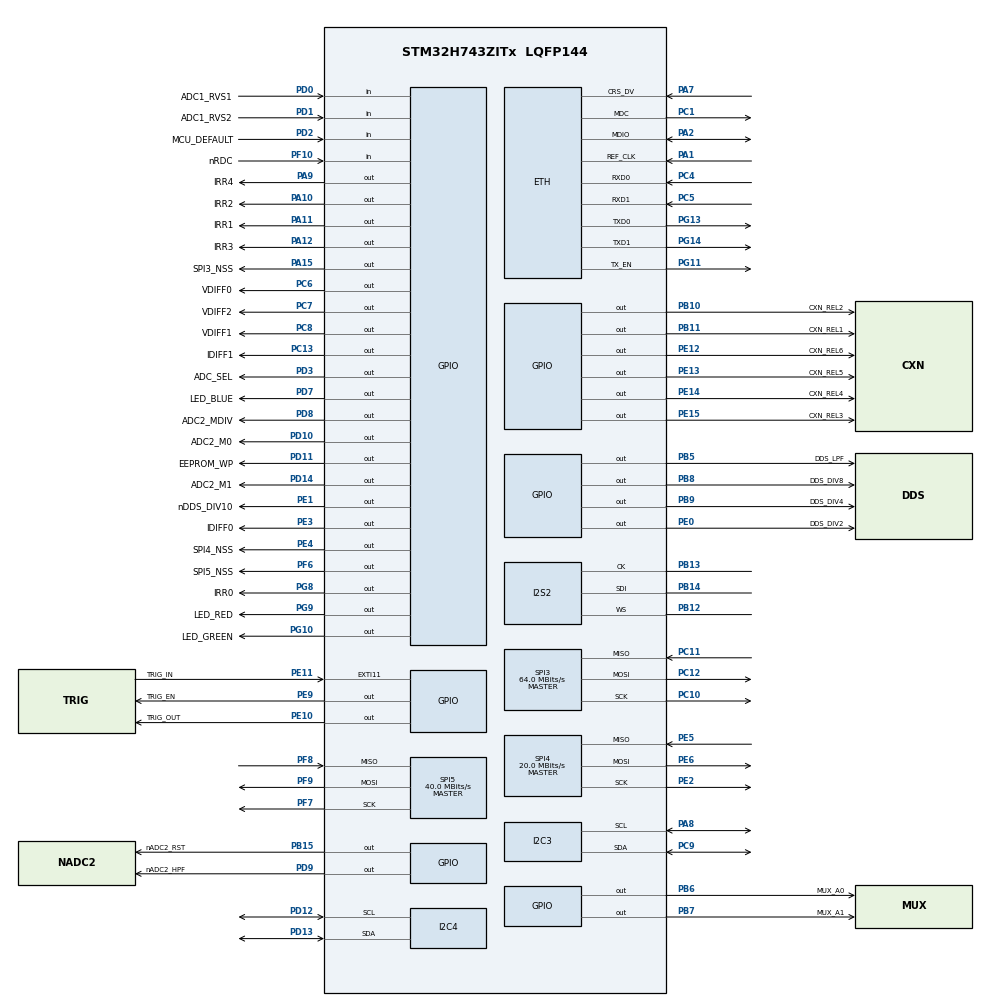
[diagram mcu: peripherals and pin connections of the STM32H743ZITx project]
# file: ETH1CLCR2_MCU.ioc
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CORTEX_M7.AccessPermission-Cortex_Memory_Protection_Unit_Region0_Settings=MPU_REGION_FULL_ACCESS
CORTEX_M7.AccessPermission-Cortex_Memory_Protection_Unit_Region1_Settings=MPU_REGION_FULL_ACCESS
CORTEX_M7.BaseAddress-Cortex_Memory_Protection_Unit_Region0_Settings=0x30040000
CORTEX_M7.BaseAddress-Cortex_Memory_Protection_Unit_Region1_Settings=0x30040000
CORTEX_M7.CPU_DCache=Enabled
CORTEX_M7.CPU_ICache=Enabled
CORTEX_M7.DisableExec-Cortex_Memory_Protection_Unit_Region0_Settings=MPU_INSTRUCTION_ACCESS_DISABLE
CORTEX_M7.DisableExec-Cortex_Memory_Protection_Unit_Region1_Settings=MPU_INSTRUCTION_ACCESS_DISABLE
CORTEX_M7.Enable-Cortex_Memory_Protection_Unit_Region0_Settings=MPU_REGION_ENABLE
CORTEX_M7.Enable-Cortex_Memory_Protection_Unit_Region1_Settings=MPU_REGION_ENABLE
CORTEX_M7.IsBufferable-Cortex_Memory_Protection_Unit_Region1_Settings=MPU_ACCESS_BUFFERABLE
CORTEX_M7.IsShareable-Cortex_Memory_Protection_Unit_Region1_Settings=MPU_ACCESS_SHAREABLE
CORTEX_M7.MPU_Control=MPU_PRIVILEGED_DEFAULT
CORTEX_M7.Size-Cortex_Memory_Protection_Unit_Region0_Settings=MPU_REGION_SIZE_32KB
CORTEX_M7.Size-Cortex_Memory_Protection_Unit_Region1_Settings=MPU_REGION_SIZE_256B
CORTEX_M7.TypeExtField-Cortex_Memory_Protection_Unit_Region0_Settings=MPU_TEX_LEVEL1
ETH.MediaInterface=HAL_ETH_RMII_MODE
FREERTOS.Queues01=QueueTrigger,1,uint8_t,0,Static,QueueTriggerBuffer,QueueTriggerControlBlock
FREERTOS.Tasks01=defaultTask,24,128,StartDefaultTask,Default,NULL,Dynamic,NULL,NULL;LEDTask,8,256,StartLEDTask,Default,NULL,Dynamic,NULL,NULL;TriggerTask,40,128,StartTriggerTask,Default,NULL,Dynamic,NULL,NULL
FREERTOS.configUSE_NEWLIB_REENTRANT=1
I2C3.Timing=0x00C0EAFF
I2C4.Timing=0x10C0ECFF
I2S2.AudioFreq=AudioFreqCustomValue
I2S2.AudioFreqCustom=64062
I2S2.CPOL=I2S_CPOL_LOW
I2S2.Data24BitAlignment=I2S_DATA_24BIT_ALIGNMENT_RIGHT
I2S2.DataFormat=I2S_DATAFORMAT_24B
I2S2.ErrorAudioFreq=0.8 %
I2S2.Instance=SPI$Index
I2S2.MasterKeepIOState=I2S_MASTER_KEEP_IO_STATE_DISABLE
I2S2.RealAudioFreq=64.516 KHz
I2S2.Standard=I2S_STANDARD_PHILIPS
LWIP.BSP.number=1
LWIP.GATEWAY_ADDRESS=192.168.001.001
LWIP.IP_ADDRESS=192.168.001.126
LWIP.LWIP_DHCP=0
LWIP.MEM_SIZE=16360
LWIP.NETMASK_ADDRESS=255.255.255.000
LWIP.TCPIP_THREAD_STACKSIZE=2048
LWIP.Version=v2.1.2_Cube
LWIP0.BSP.STBoard=false
LWIP0.BSP.api=BSP_COMPONENT_DRIVER
LWIP0.BSP.component=LAN8742
LWIP0.BSP.instance=LAN8742
LWIP0.BSP.name=Driver_PHY
LWIP0.BSP.solution=LAN8742
Mcu.Family=STM32H7
Mcu.Name=STM32H743ZITx
Mcu.Package=LQFP144
NVIC.ETH_IRQn=true\:5\:0\:false\:false\:true\:true\:true\:true\:true
NVIC.EXTI15_10_IRQn=true\:5\:0\:false\:false\:true\:true\:true\:true\:true
NVIC.PriorityGroup=NVIC_PRIORITYGROUP_4
NVIC.TIM1_UP_IRQn=true\:15\:0\:false\:false\:true\:false\:false\:true\:true
NVIC.TimeBase=TIM1_UP_IRQn
NVIC.TimeBaseIP=TIM1
PA1.GPIO_Speed=GPIO_SPEED_FREQ_VERY_HIGH
PA1.Mode=RMII
PA1.Signal=ETH_REF_CLK
PA10.GPIO_Label=IRR2
PA10.PinState=GPIO_PIN_SET
PA10.Signal=GPIO_Output
PA11.GPIO_Label=IRR1
PA11.PinState=GPIO_PIN_SET
PA11.Signal=GPIO_Output
PA12.GPIO_Label=IRR3
PA12.PinState=GPIO_PIN_SET
PA12.Signal=GPIO_Output
PA13\ (JTMS/SWDIO).Signal=DEBUG_JTMS-SWDIO
PA14\ (JTCK/SWCLK).Signal=DEBUG_JTCK-SWCLK
PA15\ (JTDI).GPIO_Label=SPI3_NSS
PA15\ (JTDI).GPIO_PuPd=GPIO_PULLUP
PA15\ (JTDI).GPIO_Speed=GPIO_SPEED_FREQ_VERY_HIGH
PA15\ (JTDI).PinState=GPIO_PIN_SET
PA15\ (JTDI).Signal=GPIO_Output
PA2.GPIO_Speed=GPIO_SPEED_FREQ_VERY_HIGH
PA2.Mode=RMII
PA2.Signal=ETH_MDIO
PA7.GPIO_Speed=GPIO_SPEED_FREQ_VERY_HIGH
PA7.Mode=RMII
PA7.Signal=ETH_CRS_DV
PA8.GPIO_Pu=GPIO_PULLUP
PA8.Mode=I2C
PA8.Signal=I2C3_SCL
PA9.GPIO_Label=IRR4
PA9.Signal=GPIO_Output
PB10.GPIO_Label=CXN_REL2
PB10.Signal=GPIO_Output
PB11.GPIO_Label=CXN_REL1
PB11.Signal=GPIO_Output
PB12.GPIO_Speed=GPIO_SPEED_FREQ_HIGH
PB12.Mode=Half_Duplex_Master_Rx
PB12.Signal=I2S2_WS
PB13.GPIO_Speed=GPIO_SPEED_FREQ_HIGH
PB13.Mode=Half_Duplex_Master_Rx
PB13.Signal=I2S2_CK
PB14.GPIO_PuPd=GPIO_NOPULL
PB14.GPIO_Speed=GPIO_SPEED_FREQ_HIGH
PB14.Mode=Half_Duplex_Master_Rx
PB14.Signal=I2S2_SDI
PB15.GPIO_Label=nADC2_RST
PB15.Signal=GPIO_Output
PB5.GPIO_Label=DDS_LPF
PB5.Signal=GPIO_Output
PB6.GPIO_Label=MUX_A0
PB6.Signal=GPIO_Output
PB7.GPIO_Label=MUX_A1
PB7.Signal=GPIO_Output
PB8.GPIO_Label=DDS_DIV8
PB8.PinState=GPIO_PIN_SET
PB8.Signal=GPIO_Output
PB9.GPIO_Label=DDS_DIV4
PB9.PinState=GPIO_PIN_SET
PB9.Signal=GPIO_Output
PC1.Mode=RMII
PC1.Signal=ETH_MDC
PC10.GPIO_Speed=GPIO_SPEED_FREQ_HIGH
PC10.Mode=Full_Duplex_Master
PC10.Signal=SPI3_SCK
PC11.GPIO_Speed=GPIO_SPEED_FREQ_HIGH
PC11.Mode=Full_Duplex_Master
PC11.Signal=SPI3_MISO
PC12.GPIO_Speed=GPIO_SPEED_FREQ_HIGH
PC12.Mode=Full_Duplex_Master
PC12.Signal=SPI3_MOSI
PC13.GPIO_Label=IDIFF1
PC13.Signal=GPIO_Output
PC4.GPIO_Speed=GPIO_SPEED_FREQ_VERY_HIGH
PC4.Mode=RMII
PC4.Signal=ETH_RXD0
PC5.GPIO_Speed=GPIO_SPEED_FREQ_VERY_HIGH
PC5.Mode=RMII
PC5.Signal=ETH_RXD1
PC6.GPIO_Label=VDIFF0
PC6.Signal=GPIO_Output
PC7.GPIO_Label=VDIFF2
PC7.Signal=GPIO_Output
PC8.GPIO_Label=VDIFF1
PC8.PinState=GPIO_PIN_RESET
PC8.Signal=GPIO_Output
PC9.GPIO_Pu=GPIO_PULLUP
PC9.Mode=I2C
PC9.Signal=I2C3_SDA
PD0.GPIO_Label=ADC1_RVS1
PD0.Signal=GPIO_Input
PD1.GPIO_Label=ADC1_RVS2
PD1.Signal=GPIO_Input
PD10.GPIO_Label=ADC2_M0
PD10.Signal=GPIO_Output
PD11.GPIO_Label=EEPROM_WP
PD11.Signal=GPIO_Output
PD12.GPIO_Pu=GPIO_PULLUP
PD12.Mode=I2C
PD12.Signal=I2C4_SCL
PD13.GPIO_Pu=GPIO_PULLUP
PD13.Mode=I2C
PD13.Signal=I2C4_SDA
PD14.GPIO_Label=ADC2_M1
PD14.Signal=GPIO_Output
PD2.GPIO_Label=MCU_DEFAULT
PD2.Signal=GPIO_Input
PD3.GPIO_Label=ADC_SEL
PD3.GPIO_Speed=GPIO_SPEED_FREQ_LOW
PD3.PinState=GPIO_PIN_RESET
PD3.Signal=GPIO_Output
PD7.GPIO_Label=LED_BLUE
PD7.PinState=GPIO_PIN_SET
PD7.Signal=GPIO_Output
PD8.GPIO_Label=ADC2_MDIV
PD8.Signal=GPIO_Output
PD9.GPIO_Label=nADC2_HPF
PD9.Signal=GPIO_Output
PE0.GPIO_Label=DDS_DIV2
PE0.PinState=GPIO_PIN_SET
PE0.Signal=GPIO_Output
PE1.GPIO_Label=nDDS_DIV10
PE1.PinState=GPIO_PIN_SET
PE1.Signal=GPIO_Output
PE10.GPIO_Label=TRIG_OUT
PE10.Signal=GPIO_Output
PE11.GPIO_Label=TRIG_IN
PE11.Signal=GPXTI11
PE12.GPIO_Label=CXN_REL6
PE12.Signal=GPIO_Output
PE13.GPIO_Label=CXN_REL5
PE13.Signal=GPIO_Output
PE14.GPIO_Label=CXN_REL4
PE14.Signal=GPIO_Output
PE15.GPIO_Label=CXN_REL3
PE15.Signal=GPIO_Output
PE2.GPIO_PuPd=GPIO_PULLUP
PE2.GPIO_Speed=GPIO_SPEED_FREQ_HIGH
PE2.Mode=Full_Duplex_Master
PE2.Signal=SPI4_SCK
PE3.GPIO_Label=IDIFF0
PE3.Signal=GPIO_Output
PE4.GPIO_Label=SPI4_NSS
PE4.GPIO_PuPd=GPIO_PULLUP
PE4.GPIO_Speed=GPIO_SPEED_FREQ_HIGH
PE4.PinState=GPIO_PIN_SET
PE4.Signal=GPIO_Output
PE5.GPIO_Speed=GPIO_SPEED_FREQ_HIGH
PE5.Mode=Full_Duplex_Master
PE5.Signal=SPI4_MISO
PE6.GPIO_Speed=GPIO_SPEED_FREQ_HIGH
PE6.Mode=Full_Duplex_Master
PE6.Signal=SPI4_MOSI
PE9.GPIO_Label=TRIG_EN
PE9.PinState=GPIO_PIN_SET
PE9.Signal=GPIO_Output
PF10.GPIO_Label=nRDC
PF10.Signal=GPIO_Input
PF6.GPIO_Label=SPI5_NSS
PF6.GPIO_PuPd=GPIO_PULLUP
PF6.PinState=GPIO_PIN_SET
PF6.Signal=GPIO_Output
PF7.GPIO_Speed=GPIO_SPEED_FREQ_HIGH
PF7.Mode=Full_Duplex_Master
PF7.Signal=SPI5_SCK
PF8.GPIO_Speed=GPIO_SPEED_FREQ_HIGH
PF8.Mode=Full_Duplex_Master
PF8.Signal=SPI5_MISO
PF9.GPIO_Speed=GPIO_SPEED_FREQ_HIGH
PF9.Mode=Full_Duplex_Master
PF9.Signal=SPI5_MOSI
PG10.GPIO_Label=LED_GREEN
PG10.PinState=GPIO_PIN_SET
PG10.Signal=GPIO_Output
PG11.GPIO_Speed=GPIO_SPEED_FREQ_VERY_HIGH
PG11.Mode=RMII
PG11.Signal=ETH_TX_EN
PG13.GPIO_Speed=GPIO_SPEED_FREQ_VERY_HIGH
PG13.Mode=RMII
PG13.Signal=ETH_TXD0
PG14.GPIO_Speed=GPIO_SPEED_FREQ_VERY_HIGH
PG14.Mode=RMII
PG14.Signal=ETH_TXD1
PG8.GPIO_Label=IRR0
PG8.PinState=GPIO_PIN_RESET
PG8.Signal=GPIO_Output
PG9.GPIO_Label=LED_RED
PG9.PinState=GPIO_PIN_SET
PG9.Signal=GPIO_Output
PH0-OSC_IN\ (PH0).Mode=HSE-External-Oscillator
PH0-OSC_IN\ (PH0).Signal=RCC_OSC_IN
PH1-OSC_OUT\ (PH1).Mode=HSE-External-Oscillator
PH1-OSC_OUT\ (PH1).Signal=RCC_OSC_OUT
ProjectManager.HeapSize=0x200
ProjectManager.StackSize=0x400
ProjectManager.TargetToolchain=STM32CubeIDE
RCC.ADCFreq_Value=128000000
RCC.APB1Freq_Value=50000000
RCC.APB2Freq_Value=100000000
RCC.APB3Freq_Value=100000000
RCC.APB4Freq_Value=100000000
RCC.CortexFreq_Value=400000000
RCC.D1PPRE=RCC_APB3_DIV2
RCC.D2PPRE1=RCC_APB1_DIV4
RCC.D2PPRE2=RCC_APB2_DIV2
RCC.D3PPRE=RCC_APB4_DIV2
RCC.DIVM1=8
RCC.DIVM2=4
RCC.DIVM3=4
RCC.DIVN1=400
RCC.DIVN2=128
RCC.DIVN3=120
RCC.DIVP2=4
RCC.DIVQ1=4
RCC.DIVQ2=4
RCC.DIVQ3=6
RCC.EnbaleCSS=true
RCC.HCLKFreq_Value=200000000
RCC.HPRE=RCC_HCLK_DIV2
RCC.HSE_VALUE=16000000
RCC.PLL2FRACN=0
RCC.PLL3FRACN=0
RCC.PLLFRACN=0
RCC.PLLSourceVirtual=RCC_PLLSOURCE_HSE
RCC.SPI123CLockSelection=RCC_SPI123CLKSOURCE_PLL2
RCC.SYSCLKFreq_VALUE=400000000
RCC.SYSCLKSource=RCC_SYSCLKSOURCE_PLLCLK
RCC.Spi45ClockSelection=RCC_SPI45CLKSOURCE_PLL3
RCC.USBFreq_Value=200000000
SPI3.BaudRatePrescaler=SPI_BAUDRATEPRESCALER_2
SPI3.CalculateBaudRate=64.0 MBits/s
SPI3.DataSize=SPI_DATASIZE_32BIT
SPI3.Direction=SPI_DIRECTION_2LINES
SPI3.Mode=SPI_MODE_MASTER
SPI3.VirtualType=VM_MASTER
SPI4.BaudRatePrescaler=SPI_BAUDRATEPRESCALER_4
SPI4.CLKPhase=SPI_PHASE_1EDGE
SPI4.CLKPolarity=SPI_POLARITY_HIGH
SPI4.CalculateBaudRate=20.0 MBits/s
SPI4.DataSize=SPI_DATASIZE_16BIT
SPI4.Direction=SPI_DIRECTION_2LINES
SPI4.Mode=SPI_MODE_MASTER
SPI4.VirtualType=VM_MASTER
SPI5.BaudRatePrescaler=SPI_BAUDRATEPRESCALER_2
SPI5.CLKPhase=SPI_PHASE_2EDGE
SPI5.CalculateBaudRate=40.0 MBits/s
SPI5.DataSize=SPI_DATASIZE_16BIT
SPI5.Direction=SPI_DIRECTION_2LINES
SPI5.Mode=SPI_MODE_MASTER
SPI5.VirtualType=VM_MASTER
VP_FREERTOS_VS_CMSIS_V2.Mode=CMSIS_V2
VP_LWIP_VS_Enabled.Mode=Enabled
VP_SYS_VS_tim1.Mode=TIM1
board=custom

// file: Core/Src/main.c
/* USER CODE BEGIN Header */
/**
  ******************************************************************************
  * @file           : main.c
  * @brief          : Main program body
  ******************************************************************************
  * @attention
  *
  * <h2><center>&copy; Copyright (c) 2021 STMicroelectronics.
  * All rights reserved.</center></h2>
  *
  * This software component is licensed by ST under BSD 3-Clause license,
  * the "License"; You may not use this file except in compliance with the
  * License. You may obtain a copy of the License at:
  *                        opensource.org/licenses/BSD-3-Clause
  *
  ******************************************************************************
  */
/* USER CODE END Header */
#include "main.h"
#include "cmsis_os.h"
#include "lwip.h"

/* USER CODE BEGIN Includes */
#include "scpi_server.h"
#include "bsp.h"
#include "ADS8681.h"
#include "AD9834.h"
#include "dwt_delay.h"
#include "CS5361.h"
#include "IV_Converter.h"
#include "relays.h"
/* USER CODE END Includes */

typedef StaticQueue_t osStaticMessageQDef_t;

I2C_HandleTypeDef hi2c3;
I2C_HandleTypeDef hi2c4;

I2S_HandleTypeDef hi2s2;

SPI_HandleTypeDef hspi4;
SPI_HandleTypeDef hspi5;

/* Definitions for defaultTask */
osThreadId_t defaultTaskHandle;
const osThreadAttr_t defaultTask_attributes = {
  .name = "defaultTask",
  .stack_size = 128 * 4,
  .priority = (osPriority_t) osPriorityNormal,
};
/* Definitions for LEDTask */
osThreadId_t LEDTaskHandle;
const osThreadAttr_t LEDTask_attributes = {
  .name = "LEDTask",
  .stack_size = 256 * 4,
  .priority = (osPriority_t) osPriorityLow,
};
/* Definitions for TriggerTask */
osThreadId_t TriggerTaskHandle;
const osThreadAttr_t TriggerTask_attributes = {
  .name = "TriggerTask",
  .stack_size = 128 * 4,
  .priority = (osPriority_t) osPriorityHigh,
};
/* Definitions for QueueTrigger */
osMessageQueueId_t QueueTriggerHandle;
uint8_t QueueTriggerBuffer[ 1 * sizeof( uint8_t ) ];
osStaticMessageQDef_t QueueTriggerControlBlock;
const osMessageQueueAttr_t QueueTrigger_attributes = {
  .name = "QueueTrigger",
  .cb_mem = &QueueTriggerControlBlock,
  .cb_size = sizeof(QueueTriggerControlBlock),
  .mq_mem = &QueueTriggerBuffer,
  .mq_size = sizeof(QueueTriggerBuffer)
};

void SystemClock_Config(void);
void PeriphCommonClock_Config(void);
static void MPU_Config(void);
static void MX_GPIO_Init(void);
static void MX_I2C3_Init(void);
static void MX_I2C4_Init(void);
static void MX_SPI3_Init(void);
static void MX_SPI4_Init(void);
static void MX_SPI5_Init(void);
static void MX_I2S2_Init(void);
void StartDefaultTask(void *argument);
void StartLEDTask(void *argument);
void StartTriggerTask(void *argument);

int main(void)
{

  /* MPU Configuration--------------------------------------------------------*/
  MPU_Config();

  /* Enable I-Cache---------------------------------------------------------*/
  SCB_EnableICache();

  /* Enable D-Cache---------------------------------------------------------*/
  SCB_EnableDCache();

  /* MCU Configuration--------------------------------------------------------*/

  /* Reset of all peripherals, Initializes the Flash interface and the Systick. */
  HAL_Init();

  /* Configure the system clock */
  SystemClock_Config();

/* Configure the peripherals common clocks */
  PeriphCommonClock_Config();

  /* Initialize all configured peripherals */
  MX_GPIO_Init();
  MX_I2C3_Init();
  MX_I2C4_Init();
  MX_SPI3_Init();
  MX_SPI4_Init();
  MX_SPI5_Init();
  MX_I2S2_Init();
  /* USER CODE BEGIN 2 */
  HAL_Delay(100);
  MX_LWIP_Init();
  DWT_Init();
  BSP_Init();
  ADS8681_Init();
  AD9834_Init();
  CS5361_Init();
  IV_Converter(R1k);
  CXN_Relays_AllOn();
  /* USER CODE END 2 */

  /* Init scheduler */
  osKernelInitialize();

  /* Create the queue(s) */
  /* creation of QueueTrigger */
  QueueTriggerHandle = osMessageQueueNew (1, sizeof(uint8_t), &QueueTrigger_attributes);

  /* Create the thread(s) */
  /* creation of defaultTask */
  defaultTaskHandle = osThreadNew(StartDefaultTask, NULL, &defaultTask_attributes);

  /* creation of LEDTask */
  LEDTaskHandle = osThreadNew(StartLEDTask, NULL, &LEDTask_attributes);

  /* creation of TriggerTask */
  TriggerTaskHandle = osThreadNew(StartTriggerTask, NULL, &TriggerTask_attributes);

  /* USER CODE BEGIN RTOS_THREADS */
  /* add threads, ... */
  scpi_server_init();
  osThreadSuspend(TriggerTaskHandle);
  /* USER CODE END RTOS_THREADS */

  /* Start scheduler */
  osKernelStart();

  /* We should never get here as control is now taken by the scheduler */
  /* Infinite loop */
  while (1)
  {

  }
}

void SystemClock_Config(void)
{
  RCC_OscInitTypeDef RCC_OscInitStruct = {0};
  RCC_ClkInitTypeDef RCC_ClkInitStruct = {0};

  /** Supply configuration update enable
  */
  HAL_PWREx_ConfigSupply(PWR_LDO_SUPPLY);

  /** Configure the main internal regulator output voltage
  */
  __HAL_PWR_VOLTAGESCALING_CONFIG(PWR_REGULATOR_VOLTAGE_SCALE1);

  while(!__HAL_PWR_GET_FLAG(PWR_FLAG_VOSRDY)) {}

  /** Macro to configure the PLL clock source
  */
  __HAL_RCC_PLL_PLLSOURCE_CONFIG(RCC_PLLSOURCE_HSE);

  /** Initializes the RCC Oscillators according to the specified parameters
  * in the RCC_OscInitTypeDef structure.
  */
  RCC_OscInitStruct.OscillatorType = RCC_OSCILLATORTYPE_HSE;
  RCC_OscInitStruct.HSEState = RCC_HSE_ON;
  RCC_OscInitStruct.PLL.PLLState = RCC_PLL_ON;
  RCC_OscInitStruct.PLL.PLLSource = RCC_PLLSOURCE_HSE;
  RCC_OscInitStruct.PLL.PLLM = 8;
  RCC_OscInitStruct.PLL.PLLN = 400;
  RCC_OscInitStruct.PLL.PLLP = 2;
  RCC_OscInitStruct.PLL.PLLQ = 4;
  RCC_OscInitStruct.PLL.PLLR = 2;
  RCC_OscInitStruct.PLL.PLLRGE = RCC_PLL1VCIRANGE_1;
  RCC_OscInitStruct.PLL.PLLVCOSEL = RCC_PLL1VCOWIDE;
  RCC_OscInitStruct.PLL.PLLFRACN = 0;
  if (HAL_RCC_OscConfig(&RCC_OscInitStruct) != HAL_OK)
  {
    Error_Handler();
  }

  /** Initializes the CPU, AHB and APB buses clocks
  */
  RCC_ClkInitStruct.ClockType = RCC_CLOCKTYPE_HCLK|RCC_CLOCKTYPE_SYSCLK
                              |RCC_CLOCKTYPE_PCLK1|RCC_CLOCKTYPE_PCLK2
                              |RCC_CLOCKTYPE_D3PCLK1|RCC_CLOCKTYPE_D1PCLK1;
  RCC_ClkInitStruct.SYSCLKSource = RCC_SYSCLKSOURCE_PLLCLK;
  RCC_ClkInitStruct.SYSCLKDivider = RCC_SYSCLK_DIV1;
  RCC_ClkInitStruct.AHBCLKDivider = RCC_HCLK_DIV2;
  RCC_ClkInitStruct.APB3CLKDivider = RCC_APB3_DIV2;
  RCC_ClkInitStruct.APB1CLKDivider = RCC_APB1_DIV4;
  RCC_ClkInitStruct.APB2CLKDivider = RCC_APB2_DIV2;
  RCC_ClkInitStruct.APB4CLKDivider = RCC_APB4_DIV2;

  if (HAL_RCC_ClockConfig(&RCC_ClkInitStruct, FLASH_LATENCY_2) != HAL_OK)
  {
    Error_Handler();
  }

  /** Enables the Clock Security System
  */
  HAL_RCC_EnableCSS();
}

void PeriphCommonClock_Config(void)
{
  RCC_PeriphCLKInitTypeDef PeriphClkInitStruct = {0};

  /** Initializes the peripherals clock
  */
  PeriphClkInitStruct.PeriphClockSelection = RCC_PERIPHCLK_SPI3|RCC_PERIPHCLK_SPI2
                              |RCC_PERIPHCLK_SPI4|RCC_PERIPHCLK_SPI5;
  PeriphClkInitStruct.PLL2.PLL2M = 4;
  PeriphClkInitStruct.PLL2.PLL2N = 128;
  PeriphClkInitStruct.PLL2.PLL2P = 4;
  PeriphClkInitStruct.PLL2.PLL2Q = 4;
  PeriphClkInitStruct.PLL2.PLL2R = 2;
  PeriphClkInitStruct.PLL2.PLL2RGE = RCC_PLL2VCIRANGE_2;
  PeriphClkInitStruct.PLL2.PLL2VCOSEL = RCC_PLL2VCOWIDE;
  PeriphClkInitStruct.PLL2.PLL2FRACN = 0;
  PeriphClkInitStruct.PLL3.PLL3M = 4;
  PeriphClkInitStruct.PLL3.PLL3N = 120;
  PeriphClkInitStruct.PLL3.PLL3P = 2;
  PeriphClkInitStruct.PLL3.PLL3Q = 6;
  PeriphClkInitStruct.PLL3.PLL3R = 2;
  PeriphClkInitStruct.PLL3.PLL3RGE = RCC_PLL3VCIRANGE_2;
  PeriphClkInitStruct.PLL3.PLL3VCOSEL = RCC_PLL3VCOWIDE;
  PeriphClkInitStruct.PLL3.PLL3FRACN = 0;
  PeriphClkInitStruct.Spi123ClockSelection = RCC_SPI123CLKSOURCE_PLL2;
  PeriphClkInitStruct.Spi45ClockSelection = RCC_SPI45CLKSOURCE_PLL3;
  if (HAL_RCCEx_PeriphCLKConfig(&PeriphClkInitStruct) != HAL_OK)
  {
    Error_Handler();
  }
}

static void MX_I2C3_Init(void)
{

  hi2c3.Instance = I2C3;
  hi2c3.Init.Timing = 0x00C0EAFF;
  hi2c3.Init.OwnAddress1 = 0;
  hi2c3.Init.AddressingMode = I2C_ADDRESSINGMODE_7BIT;
  hi2c3.Init.DualAddressMode = I2C_DUALADDRESS_DISABLE;
  hi2c3.Init.OwnAddress2 = 0;
  hi2c3.Init.OwnAddress2Masks = I2C_OA2_NOMASK;
  hi2c3.Init.GeneralCallMode = I2C_GENERALCALL_DISABLE;
  hi2c3.Init.NoStretchMode = I2C_NOSTRETCH_DISABLE;
  if (HAL_I2C_Init(&hi2c3) != HAL_OK)
  {
    Error_Handler();
  }

  /** Configure Analogue filter
  */
  if (HAL_I2CEx_ConfigAnalogFilter(&hi2c3, I2C_ANALOGFILTER_ENABLE) != HAL_OK)
  {
    Error_Handler();
  }

  /** Configure Digital filter
  */
  if (HAL_I2CEx_ConfigDigitalFilter(&hi2c3, 0) != HAL_OK)
  {
    Error_Handler();
  }

}

static void MX_I2C4_Init(void)
{

  hi2c4.Instance = I2C4;
  hi2c4.Init.Timing = 0x10C0ECFF;
  hi2c4.Init.OwnAddress1 = 0;
  hi2c4.Init.AddressingMode = I2C_ADDRESSINGMODE_7BIT;
  hi2c4.Init.DualAddressMode = I2C_DUALADDRESS_DISABLE;
  hi2c4.Init.OwnAddress2 = 0;
  hi2c4.Init.OwnAddress2Masks = I2C_OA2_NOMASK;
  hi2c4.Init.GeneralCallMode = I2C_GENERALCALL_DISABLE;
  hi2c4.Init.NoStretchMode = I2C_NOSTRETCH_DISABLE;
  if (HAL_I2C_Init(&hi2c4) != HAL_OK)
  {
    Error_Handler();
  }

  /** Configure Analogue filter
  */
  if (HAL_I2CEx_ConfigAnalogFilter(&hi2c4, I2C_ANALOGFILTER_ENABLE) != HAL_OK)
  {
    Error_Handler();
  }

  /** Configure Digital filter
  */
  if (HAL_I2CEx_ConfigDigitalFilter(&hi2c4, 0) != HAL_OK)
  {
    Error_Handler();
  }

}

static void MX_I2S2_Init(void)
{

  hi2s2.Instance = SPI2;
  hi2s2.Init.Mode = I2S_MODE_MASTER_RX;
  hi2s2.Init.Standard = I2S_STANDARD_PHILIPS;
  hi2s2.Init.DataFormat = I2S_DATAFORMAT_24B;
  hi2s2.Init.MCLKOutput = I2S_MCLKOUTPUT_DISABLE;
  hi2s2.Init.AudioFreq = 64062;
  hi2s2.Init.CPOL = I2S_CPOL_LOW;
  hi2s2.Init.FirstBit = I2S_FIRSTBIT_MSB;
  hi2s2.Init.WSInversion = I2S_WS_INVERSION_DISABLE;
  hi2s2.Init.Data24BitAlignment = I2S_DATA_24BIT_ALIGNMENT_RIGHT;
  hi2s2.Init.MasterKeepIOState = I2S_MASTER_KEEP_IO_STATE_DISABLE;
  if (HAL_I2S_Init(&hi2s2) != HAL_OK)
  {
    Error_Handler();
  }

}

static void MX_SPI3_Init(void)
{

  LL_SPI_InitTypeDef SPI_InitStruct = {0};

  LL_GPIO_InitTypeDef GPIO_InitStruct = {0};

  /* Peripheral clock enable */
  LL_APB1_GRP1_EnableClock(LL_APB1_GRP1_PERIPH_SPI3);

  LL_AHB4_GRP1_EnableClock(LL_AHB4_GRP1_PERIPH_GPIOC);
  /**SPI3 GPIO Configuration
  PC10   ------> SPI3_SCK
  PC11   ------> SPI3_MISO
  PC12   ------> SPI3_MOSI
  */
  GPIO_InitStruct.Pin = LL_GPIO_PIN_10|LL_GPIO_PIN_11|LL_GPIO_PIN_12;
  GPIO_InitStruct.Mode = LL_GPIO_MODE_ALTERNATE;
  GPIO_InitStruct.Speed = LL_GPIO_SPEED_FREQ_HIGH;
  GPIO_InitStruct.OutputType = LL_GPIO_OUTPUT_PUSHPULL;
  GPIO_InitStruct.Pull = LL_GPIO_PULL_NO;
  GPIO_InitStruct.Alternate = LL_GPIO_AF_6;
  LL_GPIO_Init(GPIOC, &GPIO_InitStruct);

  /* SPI3 parameter configuration*/
  SPI_InitStruct.TransferDirection = LL_SPI_FULL_DUPLEX;
  SPI_InitStruct.Mode = LL_SPI_MODE_MASTER;
  SPI_InitStruct.DataWidth = LL_SPI_DATAWIDTH_32BIT;
  SPI_InitStruct.ClockPolarity = LL_SPI_POLARITY_LOW;
  SPI_InitStruct.ClockPhase = LL_SPI_PHASE_1EDGE;
  SPI_InitStruct.NSS = LL_SPI_NSS_SOFT;
  SPI_InitStruct.BaudRate = LL_SPI_BAUDRATEPRESCALER_DIV2;
  SPI_InitStruct.BitOrder = LL_SPI_MSB_FIRST;
  SPI_InitStruct.CRCCalculation = LL_SPI_CRCCALCULATION_DISABLE;
  SPI_InitStruct.CRCPoly = 0x0;
  LL_SPI_Init(SPI3, &SPI_InitStruct);
  LL_SPI_SetStandard(SPI3, LL_SPI_PROTOCOL_MOTOROLA);
  LL_SPI_EnableNSSPulseMgt(SPI3);

}

static void MX_SPI4_Init(void)
{

  /* SPI4 parameter configuration*/
  hspi4.Instance = SPI4;
  hspi4.Init.Mode = SPI_MODE_MASTER;
  hspi4.Init.Direction = SPI_DIRECTION_2LINES;
  hspi4.Init.DataSize = SPI_DATASIZE_16BIT;
  hspi4.Init.CLKPolarity = SPI_POLARITY_HIGH;
  hspi4.Init.CLKPhase = SPI_PHASE_1EDGE;
  hspi4.Init.NSS = SPI_NSS_SOFT;
  hspi4.Init.BaudRatePrescaler = SPI_BAUDRATEPRESCALER_4;
  hspi4.Init.FirstBit = SPI_FIRSTBIT_MSB;
  hspi4.Init.TIMode = SPI_TIMODE_DISABLE;
  hspi4.Init.CRCCalculation = SPI_CRCCALCULATION_DISABLE;
  hspi4.Init.CRCPolynomial = 0x0;
  hspi4.Init.NSSPMode = SPI_NSS_PULSE_ENABLE;
  hspi4.Init.NSSPolarity = SPI_NSS_POLARITY_LOW;
  hspi4.Init.FifoThreshold = SPI_FIFO_THRESHOLD_01DATA;
  hspi4.Init.TxCRCInitializationPattern = SPI_CRC_INITIALIZATION_ALL_ZERO_PATTERN;
  hspi4.Init.RxCRCInitializationPattern = SPI_CRC_INITIALIZATION_ALL_ZERO_PATTERN;
  hspi4.Init.MasterSSIdleness = SPI_MASTER_SS_IDLENESS_00CYCLE;
  hspi4.Init.MasterInterDataIdleness = SPI_MASTER_INTERDATA_IDLENESS_00CYCLE;
  hspi4.Init.MasterReceiverAutoSusp = SPI_MASTER_RX_AUTOSUSP_DISABLE;
  hspi4.Init.MasterKeepIOState = SPI_MASTER_KEEP_IO_STATE_DISABLE;
  hspi4.Init.IOSwap = SPI_IO_SWAP_DISABLE;
  if (HAL_SPI_Init(&hspi4) != HAL_OK)
  {
    Error_Handler();
  }

}

static void MX_SPI5_Init(void)
{

  /* SPI5 parameter configuration*/
  hspi5.Instance = SPI5;
  hspi5.Init.Mode = SPI_MODE_MASTER;
  hspi5.Init.Direction = SPI_DIRECTION_2LINES;
  hspi5.Init.DataSize = SPI_DATASIZE_16BIT;
  hspi5.Init.CLKPolarity = SPI_POLARITY_LOW;
  hspi5.Init.CLKPhase = SPI_PHASE_2EDGE;
  hspi5.Init.NSS = SPI_NSS_SOFT;
  hspi5.Init.BaudRatePrescaler = SPI_BAUDRATEPRESCALER_2;
  hspi5.Init.FirstBit = SPI_FIRSTBIT_MSB;
  hspi5.Init.TIMode = SPI_TIMODE_DISABLE;
  hspi5.Init.CRCCalculation = SPI_CRCCALCULATION_DISABLE;
  hspi5.Init.CRCPolynomial = 0x0;
  hspi5.Init.NSSPMode = SPI_NSS_PULSE_ENABLE;
  hspi5.Init.NSSPolarity = SPI_NSS_POLARITY_LOW;
  hspi5.Init.FifoThreshold = SPI_FIFO_THRESHOLD_01DATA;
  hspi5.Init.TxCRCInitializationPattern = SPI_CRC_INITIALIZATION_ALL_ZERO_PATTERN;
  hspi5.Init.RxCRCInitializationPattern = SPI_CRC_INITIALIZATION_ALL_ZERO_PATTERN;
  hspi5.Init.MasterSSIdleness = SPI_MASTER_SS_IDLENESS_00CYCLE;
  hspi5.Init.MasterInterDataIdleness = SPI_MASTER_INTERDATA_IDLENESS_00CYCLE;
  hspi5.Init.MasterReceiverAutoSusp = SPI_MASTER_RX_AUTOSUSP_DISABLE;
  hspi5.Init.MasterKeepIOState = SPI_MASTER_KEEP_IO_STATE_DISABLE;
  hspi5.Init.IOSwap = SPI_IO_SWAP_DISABLE;
  if (HAL_SPI_Init(&hspi5) != HAL_OK)
  {
    Error_Handler();
  }

}

static void MX_GPIO_Init(void)
{
  LL_EXTI_InitTypeDef EXTI_InitStruct = {0};
  LL_GPIO_InitTypeDef GPIO_InitStruct = {0};

  /* GPIO Ports Clock Enable */
  LL_AHB4_GRP1_EnableClock(LL_AHB4_GRP1_PERIPH_GPIOE);
  LL_AHB4_GRP1_EnableClock(LL_AHB4_GRP1_PERIPH_GPIOC);
  LL_AHB4_GRP1_EnableClock(LL_AHB4_GRP1_PERIPH_GPIOF);
  LL_AHB4_GRP1_EnableClock(LL_AHB4_GRP1_PERIPH_GPIOH);
  LL_AHB4_GRP1_EnableClock(LL_AHB4_GRP1_PERIPH_GPIOA);
  LL_AHB4_GRP1_EnableClock(LL_AHB4_GRP1_PERIPH_GPIOB);
  LL_AHB4_GRP1_EnableClock(LL_AHB4_GRP1_PERIPH_GPIOD);
  LL_AHB4_GRP1_EnableClock(LL_AHB4_GRP1_PERIPH_GPIOG);

  /**/
  LL_GPIO_ResetOutputPin(GPIOE, IDIFF0_Pin|TRIG_OUT_Pin|CXN_REL6_Pin|CXN_REL5_Pin
                          |CXN_REL4_Pin|CXN_REL3_Pin);

  /**/
  LL_GPIO_ResetOutputPin(GPIOC, IDIFF1_Pin|VDIFF0_Pin|VDIFF2_Pin|VDIFF1_Pin);

  /**/
  LL_GPIO_ResetOutputPin(GPIOB, CXN_REL2_Pin|CXN_REL1_Pin|nADC2_RST_Pin|DDS_LPF_Pin
                          |MUX_A0_Pin|MUX_A1_Pin);

  /**/
  LL_GPIO_ResetOutputPin(GPIOD, ADC2_MDIV_Pin|nADC2_HPF_Pin|ADC2_M0_Pin|EEPROM_WP_Pin
                          |ADC2_M1_Pin|ADC_SEL_Pin);

  /**/
  LL_GPIO_ResetOutputPin(IRR0_GPIO_Port, IRR0_Pin);

  /**/
  LL_GPIO_ResetOutputPin(IRR4_GPIO_Port, IRR4_Pin);

  /**/
  LL_GPIO_SetOutputPin(GPIOE, SPI4_NSS_Pin|TRIG_EN_Pin|DDS_DIV2_Pin|nDDS_DIV10_Pin);

  /**/
  LL_GPIO_SetOutputPin(SPI5_NSS_GPIO_Port, SPI5_NSS_Pin);

  /**/
  LL_GPIO_SetOutputPin(GPIOA, IRR2_Pin|IRR1_Pin|IRR3_Pin|SPI3_NSS_Pin);

  /**/
  LL_GPIO_SetOutputPin(LED_BLUE_GPIO_Port, LED_BLUE_Pin);

  /**/
  LL_GPIO_SetOutputPin(GPIOG, LED_RED_Pin|LED_GREEN_Pin);

  /**/
  LL_GPIO_SetOutputPin(GPIOB, DDS_DIV8_Pin|DDS_DIV4_Pin);

  /**/
  GPIO_InitStruct.Pin = IDIFF0_Pin|TRIG_EN_Pin|TRIG_OUT_Pin|CXN_REL6_Pin
                          |CXN_REL5_Pin|CXN_REL4_Pin|CXN_REL3_Pin|DDS_DIV2_Pin
                          |nDDS_DIV10_Pin;
  GPIO_InitStruct.Mode = LL_GPIO_MODE_OUTPUT;
  GPIO_InitStruct.Speed = LL_GPIO_SPEED_FREQ_LOW;
  GPIO_InitStruct.OutputType = LL_GPIO_OUTPUT_PUSHPULL;
  GPIO_InitStruct.Pull = LL_GPIO_PULL_NO;
  LL_GPIO_Init(GPIOE, &GPIO_InitStruct);

  /**/
  GPIO_InitStruct.Pin = SPI4_NSS_Pin;
  GPIO_InitStruct.Mode = LL_GPIO_MODE_OUTPUT;
  GPIO_InitStruct.Speed = LL_GPIO_SPEED_FREQ_HIGH;
  GPIO_InitStruct.OutputType = LL_GPIO_OUTPUT_PUSHPULL;
  GPIO_InitStruct.Pull = LL_GPIO_PULL_UP;
  LL_GPIO_Init(SPI4_NSS_GPIO_Port, &GPIO_InitStruct);

  /**/
  GPIO_InitStruct.Pin = IDIFF1_Pin|VDIFF0_Pin|VDIFF2_Pin|VDIFF1_Pin;
  GPIO_InitStruct.Mode = LL_GPIO_MODE_OUTPUT;
  GPIO_InitStruct.Speed = LL_GPIO_SPEED_FREQ_LOW;
  GPIO_InitStruct.OutputType = LL_GPIO_OUTPUT_PUSHPULL;
  GPIO_InitStruct.Pull = LL_GPIO_PULL_NO;
  LL_GPIO_Init(GPIOC, &GPIO_InitStruct);

  /**/
  GPIO_InitStruct.Pin = SPI5_NSS_Pin;
  GPIO_InitStruct.Mode = LL_GPIO_MODE_OUTPUT;
  GPIO_InitStruct.Speed = LL_GPIO_SPEED_FREQ_LOW;
  GPIO_InitStruct.OutputType = LL_GPIO_OUTPUT_PUSHPULL;
  GPIO_InitStruct.Pull = LL_GPIO_PULL_UP;
  LL_GPIO_Init(SPI5_NSS_GPIO_Port, &GPIO_InitStruct);

  /**/
  GPIO_InitStruct.Pin = nRDC_Pin;
  GPIO_InitStruct.Mode = LL_GPIO_MODE_INPUT;
  GPIO_InitStruct.Pull = LL_GPIO_PULL_NO;
  LL_GPIO_Init(nRDC_GPIO_Port, &GPIO_InitStruct);

  /**/
  GPIO_InitStruct.Pin = CXN_REL2_Pin|CXN_REL1_Pin|nADC2_RST_Pin|DDS_LPF_Pin
                          |MUX_A0_Pin|MUX_A1_Pin|DDS_DIV8_Pin|DDS_DIV4_Pin;
  GPIO_InitStruct.Mode = LL_GPIO_MODE_OUTPUT;
  GPIO_InitStruct.Speed = LL_GPIO_SPEED_FREQ_LOW;
  GPIO_InitStruct.OutputType = LL_GPIO_OUTPUT_PUSHPULL;
  GPIO_InitStruct.Pull = LL_GPIO_PULL_NO;
  LL_GPIO_Init(GPIOB, &GPIO_InitStruct);

  /**/
  GPIO_InitStruct.Pin = ADC2_MDIV_Pin|nADC2_HPF_Pin|ADC2_M0_Pin|EEPROM_WP_Pin
                          |ADC2_M1_Pin|ADC_SEL_Pin|LED_BLUE_Pin;
  GPIO_InitStruct.Mode = LL_GPIO_MODE_OUTPUT;
  GPIO_InitStruct.Speed = LL_GPIO_SPEED_FREQ_LOW;
  GPIO_InitStruct.OutputType = LL_GPIO_OUTPUT_PUSHPULL;
  GPIO_InitStruct.Pull = LL_GPIO_PULL_NO;
  LL_GPIO_Init(GPIOD, &GPIO_InitStruct);

  /**/
  GPIO_InitStruct.Pin = IRR0_Pin|LED_RED_Pin|LED_GREEN_Pin;
  GPIO_InitStruct.Mode = LL_GPIO_MODE_OUTPUT;
  GPIO_InitStruct.Speed = LL_GPIO_SPEED_FREQ_LOW;
  GPIO_InitStruct.OutputType = LL_GPIO_OUTPUT_PUSHPULL;
  GPIO_InitStruct.Pull = LL_GPIO_PULL_NO;
  LL_GPIO_Init(GPIOG, &GPIO_InitStruct);

  /**/
  GPIO_InitStruct.Pin = IRR4_Pin|IRR2_Pin|IRR1_Pin|IRR3_Pin;
  GPIO_InitStruct.Mode = LL_GPIO_MODE_OUTPUT;
  GPIO_InitStruct.Speed = LL_GPIO_SPEED_FREQ_LOW;
  GPIO_InitStruct.OutputType = LL_GPIO_OUTPUT_PUSHPULL;
  GPIO_InitStruct.Pull = LL_GPIO_PULL_NO;
  LL_GPIO_Init(GPIOA, &GPIO_InitStruct);

  /**/
  GPIO_InitStruct.Pin = SPI3_NSS_Pin;
  GPIO_InitStruct.Mode = LL_GPIO_MODE_OUTPUT;
  GPIO_InitStruct.Speed = LL_GPIO_SPEED_FREQ_VERY_HIGH;
  GPIO_InitStruct.OutputType = LL_GPIO_OUTPUT_PUSHPULL;
  GPIO_InitStruct.Pull = LL_GPIO_PULL_UP;
  LL_GPIO_Init(SPI3_NSS_GPIO_Port, &GPIO_InitStruct);

  /**/
  GPIO_InitStruct.Pin = ADC1_RVS1_Pin|ADC1_RVS2_Pin|MCU_DEFAULT_Pin;
  GPIO_InitStruct.Mode = LL_GPIO_MODE_INPUT;
  GPIO_InitStruct.Pull = LL_GPIO_PULL_NO;
  LL_GPIO_Init(GPIOD, &GPIO_InitStruct);

  /**/
  LL_SYSCFG_SetEXTISource(LL_SYSCFG_EXTI_PORTE, LL_SYSCFG_EXTI_LINE11);

  /**/
  EXTI_InitStruct.Line_0_31 = LL_EXTI_LINE_11;
  EXTI_InitStruct.Line_32_63 = LL_EXTI_LINE_NONE;
  EXTI_InitStruct.Line_64_95 = LL_EXTI_LINE_NONE;
  EXTI_InitStruct.LineCommand = ENABLE;
  EXTI_InitStruct.Mode = LL_EXTI_MODE_IT;
  EXTI_InitStruct.Trigger = LL_EXTI_TRIGGER_RISING;
  LL_EXTI_Init(&EXTI_InitStruct);

  /**/
  LL_GPIO_SetPinPull(TRIG_IN_GPIO_Port, TRIG_IN_Pin, LL_GPIO_PULL_NO);

  /**/
  LL_GPIO_SetPinMode(TRIG_IN_GPIO_Port, TRIG_IN_Pin, LL_GPIO_MODE_INPUT);

  /* EXTI interrupt init*/
  NVIC_SetPriority(EXTI15_10_IRQn, NVIC_EncodePriority(NVIC_GetPriorityGrouping(),5, 0));
  NVIC_EnableIRQ(EXTI15_10_IRQn);

}

void StartDefaultTask(void *argument)
{
  /* init code for LWIP */
  MX_LWIP_Init();
  for(;;)
  {
    osDelay(1);
  }
}

void StartLEDTask(void *argument)
{
  /* USER CODE BEGIN StartLEDTask */
  /* Infinite loop */
  for(;;)
  {
	HAL_GPIO_TogglePin(LED_GREEN_GPIO_Port, LED_GREEN_Pin);
	osDelay(pdMS_TO_TICKS(500));
  }
  /* USER CODE END StartLEDTask */
}

void StartTriggerTask(void *argument)
{
  /* USER CODE BEGIN StartTriggerTask */
	uint8_t trigger_status = 0;
  /* Infinite loop */
  for(;;)
  {
	  if(osOK == osMessageQueueGet(QueueTriggerHandle, &trigger_status, NULL, 10U))
	  {
			LL_GPIO_TogglePin(LED_RED_GPIO_Port, LED_RED_Pin);

	  }
	  osDelay(pdMS_TO_TICKS(2));
  }
  /* USER CODE END StartTriggerTask */
}

/* MPU Configuration */

void MPU_Config(void)
{
  MPU_Region_InitTypeDef MPU_InitStruct = {0};

  /* Disables the MPU */
  HAL_MPU_Disable();

  /** Initializes and configures the Region and the memory to be protected
  */
  MPU_InitStruct.Enable = MPU_REGION_ENABLE;
  MPU_InitStruct.Number = MPU_REGION_NUMBER0;
  MPU_InitStruct.BaseAddress = 0x30040000;
  MPU_InitStruct.Size = MPU_REGION_SIZE_32KB;
  MPU_InitStruct.SubRegionDisable = 0x0;
  MPU_InitStruct.TypeExtField = MPU_TEX_LEVEL1;
  MPU_InitStruct.AccessPermission = MPU_REGION_FULL_ACCESS;
  MPU_InitStruct.DisableExec = MPU_INSTRUCTION_ACCESS_DISABLE;
  MPU_InitStruct.IsShareable = MPU_ACCESS_NOT_SHAREABLE;
  MPU_InitStruct.IsCacheable = MPU_ACCESS_NOT_CACHEABLE;
  MPU_InitStruct.IsBufferable = MPU_ACCESS_NOT_BUFFERABLE;

  HAL_MPU_ConfigRegion(&MPU_InitStruct);

  /** Initializes and configures the Region and the memory to be protected
  */
  MPU_InitStruct.Number = MPU_REGION_NUMBER1;
  MPU_InitStruct.Size = MPU_REGION_SIZE_256B;
  MPU_InitStruct.TypeExtField = MPU_TEX_LEVEL0;
  MPU_InitStruct.IsShareable = MPU_ACCESS_SHAREABLE;
  MPU_InitStruct.IsBufferable = MPU_ACCESS_BUFFERABLE;

  HAL_MPU_ConfigRegion(&MPU_InitStruct);
  /* Enables the MPU */
  HAL_MPU_Enable(MPU_PRIVILEGED_DEFAULT);

}

void HAL_TIM_PeriodElapsedCallback(TIM_HandleTypeDef *htim)
{
  if (htim->Instance == TIM1) {
    HAL_IncTick();
  }
}

void Error_Handler(void)
{
  __disable_irq();
  while (1)
  {
  }
}
